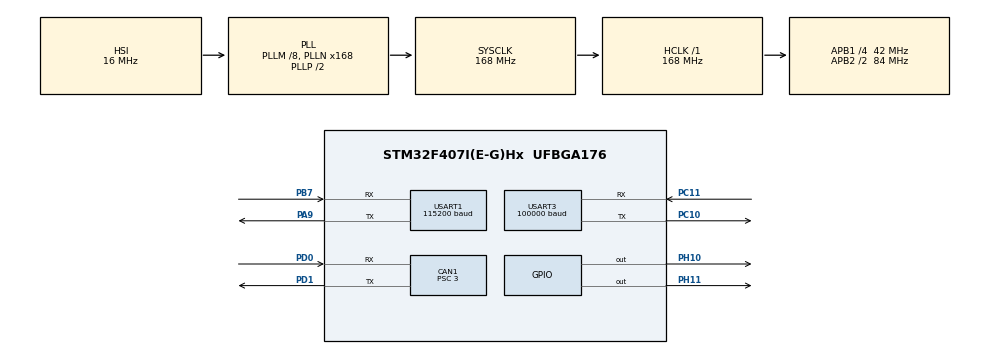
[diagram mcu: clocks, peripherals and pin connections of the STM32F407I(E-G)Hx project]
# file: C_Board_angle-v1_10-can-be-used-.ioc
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CAN1.ABOM=DISABLE
CAN1.AWUM=DISABLE
CAN1.BS1=CAN_BS1_10TQ
CAN1.BS2=CAN_BS2_3TQ
CAN1.CalculateBaudRate=1000000
CAN1.CalculateTimeQuantum=71.42857142857143
CAN1.Mode=CAN_MODE_NORMAL
CAN1.NART=DISABLE
CAN1.Prescaler=3
CAN1.RFLM=DISABLE
CAN1.SJW=CAN_SJW_1TQ
CAN1.TTCM=DISABLE
CAN1.TXFP=DISABLE
Dma.Request0=USART1_RX
Dma.Request1=USART1_TX
Dma.Request2=USART3_RX
Dma.USART1_RX.0.Direction=DMA_PERIPH_TO_MEMORY
Dma.USART1_RX.0.FIFOMode=DMA_FIFOMODE_DISABLE
Dma.USART1_RX.0.Instance=DMA2_Stream2
Dma.USART1_RX.0.MemDataAlignment=DMA_MDATAALIGN_BYTE
Dma.USART1_RX.0.MemInc=DMA_MINC_ENABLE
Dma.USART1_RX.0.Mode=DMA_NORMAL
Dma.USART1_RX.0.PeriphDataAlignment=DMA_PDATAALIGN_BYTE
Dma.USART1_RX.0.PeriphInc=DMA_PINC_DISABLE
Dma.USART1_RX.0.Priority=DMA_PRIORITY_MEDIUM
Dma.USART1_TX.1.Direction=DMA_MEMORY_TO_PERIPH
Dma.USART1_TX.1.FIFOMode=DMA_FIFOMODE_DISABLE
Dma.USART1_TX.1.Instance=DMA2_Stream7
Dma.USART1_TX.1.MemDataAlignment=DMA_MDATAALIGN_BYTE
Dma.USART1_TX.1.MemInc=DMA_MINC_ENABLE
Dma.USART1_TX.1.Mode=DMA_NORMAL
Dma.USART1_TX.1.PeriphDataAlignment=DMA_PDATAALIGN_BYTE
Dma.USART1_TX.1.PeriphInc=DMA_PINC_DISABLE
Dma.USART1_TX.1.Priority=DMA_PRIORITY_LOW
Dma.USART3_RX.2.Direction=DMA_PERIPH_TO_MEMORY
Dma.USART3_RX.2.FIFOMode=DMA_FIFOMODE_DISABLE
Dma.USART3_RX.2.Instance=DMA1_Stream1
Dma.USART3_RX.2.MemDataAlignment=DMA_MDATAALIGN_BYTE
Dma.USART3_RX.2.MemInc=DMA_MINC_ENABLE
Dma.USART3_RX.2.Mode=DMA_NORMAL
Dma.USART3_RX.2.PeriphDataAlignment=DMA_PDATAALIGN_BYTE
Dma.USART3_RX.2.PeriphInc=DMA_PINC_DISABLE
Dma.USART3_RX.2.Priority=DMA_PRIORITY_LOW
Mcu.Family=STM32F4
Mcu.Name=STM32F407I(E-G)Hx
Mcu.Package=UFBGA176
NVIC.CAN1_RX0_IRQn=true\:1\:0\:true\:false\:true\:true\:true\:true
NVIC.DMA1_Stream1_IRQn=true\:0\:0\:false\:false\:true\:false\:true\:true
NVIC.DMA2_Stream2_IRQn=true\:0\:0\:false\:false\:true\:false\:true\:true
NVIC.DMA2_Stream7_IRQn=true\:0\:0\:false\:false\:true\:false\:true\:true
NVIC.PriorityGroup=NVIC_PRIORITYGROUP_4
NVIC.TIM1_UP_TIM10_IRQn=true\:1\:0\:true\:false\:true\:true\:true\:true
NVIC.TIM7_IRQn=true\:1\:0\:true\:false\:true\:true\:true\:true
NVIC.USART1_IRQn=true\:0\:0\:true\:false\:true\:true\:true\:true
NVIC.USART3_IRQn=true\:1\:0\:true\:false\:true\:true\:true\:true
PA13.Mode=Serial_Wire
PA13.Signal=SYS_JTMS-SWDIO
PA14.Mode=Serial_Wire
PA14.Signal=SYS_JTCK-SWCLK
PA9.Mode=Asynchronous
PA9.Signal=USART1_TX
PB7.Mode=Asynchronous
PB7.Signal=USART1_RX
PC10.Mode=Asynchronous
PC10.Signal=USART3_TX
PC11.Mode=Asynchronous
PC11.Signal=USART3_RX
PD0.Mode=CAN_Activate
PD0.Signal=CAN1_RX
PD1.Mode=CAN_Activate
PD1.Signal=CAN1_TX
PH0-OSC_IN.Mode=HSE-External-Oscillator
PH0-OSC_IN.Signal=RCC_OSC_IN
PH1-OSC_OUT.Mode=HSE-External-Oscillator
PH1-OSC_OUT.Signal=RCC_OSC_OUT
PH10.Signal=GPIO_Output
PH11.Signal=GPIO_Output
ProjectManager.HeapSize=0x200
ProjectManager.StackSize=0x400
ProjectManager.TargetToolchain=CMake
RCC.48MHZClocksFreq_Value=84000000
RCC.AHBFreq_Value=168000000
RCC.APB1CLKDivider=RCC_HCLK_DIV4
RCC.APB1Freq_Value=42000000
RCC.APB1TimFreq_Value=84000000
RCC.APB2CLKDivider=RCC_HCLK_DIV2
RCC.APB2Freq_Value=84000000
RCC.APB2TimFreq_Value=168000000
RCC.CortexFreq_Value=168000000
RCC.FLatency=FLASH_LATENCY_5
RCC.HCLKFreq_Value=168000000
RCC.HSE_VALUE=25000000
RCC.HSI_VALUE=16000000
RCC.LSE_VALUE=32768
RCC.PLLM=8
RCC.PLLN=168
RCC.SYSCLKFreq_VALUE=168000000
RCC.SYSCLKSource=RCC_SYSCLKSOURCE_PLLCLK
RCC.VCOOutputFreq_Value=336000000
TIM1.AutoReloadPreload=TIM_AUTORELOAD_PRELOAD_DISABLE
TIM1.ClockDivision=TIM_CLOCKDIVISION_DIV1
TIM1.CounterMode=TIM_COUNTERMODE_UP
TIM1.Period=1000
TIM1.Prescaler=168
TIM1.RepetitionCounter=0
TIM1.TIM_MasterOutputTrigger=TIM_TRGO_RESET
TIM1.TIM_MasterSlaveMode=TIM_MASTERSLAVEMODE_DISABLE
TIM7.AutoReloadPreload=TIM_AUTORELOAD_PRELOAD_DISABLE
TIM7.CounterMode=TIM_COUNTERMODE_UP
TIM7.Period=1000
TIM7.Prescaler=168
TIM7.TIM_MasterOutputTrigger=TIM_TRGO_RESET
USART1.BaudRate=115200
USART1.Mode=MODE_TX_RX
USART1.OverSampling=UART_OVERSAMPLING_16
USART1.Parity=PARITY_NONE
USART1.StopBits=STOPBITS_1
USART1.VirtualMode=VM_ASYNC
USART1.WordLength=WORDLENGTH_8B
USART3.BaudRate=100000
USART3.Mode=MODE_TX_RX
USART3.OverSampling=UART_OVERSAMPLING_16
USART3.Parity=PARITY_NONE
USART3.StopBits=STOPBITS_1
USART3.VirtualMode=VM_ASYNC
USART3.WordLength=WORDLENGTH_9B
VP_TIM1_VS_ClockSourceINT.Mode=Internal
VP_TIM7_VS_ClockSourceINT.Mode=Enable_Timer
board=custom

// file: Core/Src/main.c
/* USER CODE BEGIN Header */
/**
  ******************************************************************************
  * @file           : main.c
  * @brief          : Main program body
  ******************************************************************************
  * @attention
  *
  * Copyright (c) 2026 STMicroelectronics.
  * All rights reserved.
  *
  * This software is licensed under terms that can be found in the LICENSE file
  * in the root directory of this software component.
  * If no LICENSE file comes with this software, it is provided AS-IS.
  *
  ******************************************************************************
  */
/* USER CODE END Header */
#include "main.h"
#include "can.h"
#include "dma.h"
#include "tim.h"
#include "usart.h"
#include "gpio.h"
#include "Task.h"

void SystemClock_Config(void);

int main(void)
{

  /* MCU Configuration--------------------------------------------------------*/

  /* Reset of all peripherals, Initializes the Flash interface and the Systick. */
  HAL_Init();

  /* Configure the system clock */
  SystemClock_Config();

  /* Initialize all configured peripherals */
  MX_GPIO_Init();
  MX_DMA_Init();
  MX_USART1_UART_Init();
  MX_CAN1_Init();
  MX_TIM1_Init();
  MX_TIM7_Init();
  MX_USART3_UART_Init();
  /* USER CODE BEGIN 2 */
  Task_Init();
  /* USER CODE END 2 */

  /* Infinite loop */
  while (1)
  {

    /* USER CODE BEGIN 3 */
    Task_loop();
  }
  /* USER CODE END 3 */
}

void SystemClock_Config(void)
{
  RCC_OscInitTypeDef RCC_OscInitStruct = {0};
  RCC_ClkInitTypeDef RCC_ClkInitStruct = {0};

  /** Configure the main internal regulator output voltage
  */
  __HAL_RCC_PWR_CLK_ENABLE();
  __HAL_PWR_VOLTAGESCALING_CONFIG(PWR_REGULATOR_VOLTAGE_SCALE1);

  /** Initializes the RCC Oscillators according to the specified parameters
  * in the RCC_OscInitTypeDef structure.
  */
  RCC_OscInitStruct.OscillatorType = RCC_OSCILLATORTYPE_HSI;
  RCC_OscInitStruct.HSIState = RCC_HSI_ON;
  RCC_OscInitStruct.HSICalibrationValue = RCC_HSICALIBRATION_DEFAULT;
  RCC_OscInitStruct.PLL.PLLState = RCC_PLL_ON;
  RCC_OscInitStruct.PLL.PLLSource = RCC_PLLSOURCE_HSI;
  RCC_OscInitStruct.PLL.PLLM = 8;
  RCC_OscInitStruct.PLL.PLLN = 168;
  RCC_OscInitStruct.PLL.PLLP = RCC_PLLP_DIV2;
  RCC_OscInitStruct.PLL.PLLQ = 4;
  if (HAL_RCC_OscConfig(&RCC_OscInitStruct) != HAL_OK)
  {
    Error_Handler();
  }

  /** Initializes the CPU, AHB and APB buses clocks
  */
  RCC_ClkInitStruct.ClockType = RCC_CLOCKTYPE_HCLK|RCC_CLOCKTYPE_SYSCLK
                              |RCC_CLOCKTYPE_PCLK1|RCC_CLOCKTYPE_PCLK2;
  RCC_ClkInitStruct.SYSCLKSource = RCC_SYSCLKSOURCE_PLLCLK;
  RCC_ClkInitStruct.AHBCLKDivider = RCC_SYSCLK_DIV1;
  RCC_ClkInitStruct.APB1CLKDivider = RCC_HCLK_DIV4;
  RCC_ClkInitStruct.APB2CLKDivider = RCC_HCLK_DIV2;

  if (HAL_RCC_ClockConfig(&RCC_ClkInitStruct, FLASH_LATENCY_5) != HAL_OK)
  {
    Error_Handler();
  }
}

void Error_Handler(void)
{
  __disable_irq();
  while (1)
  {
  }
}
